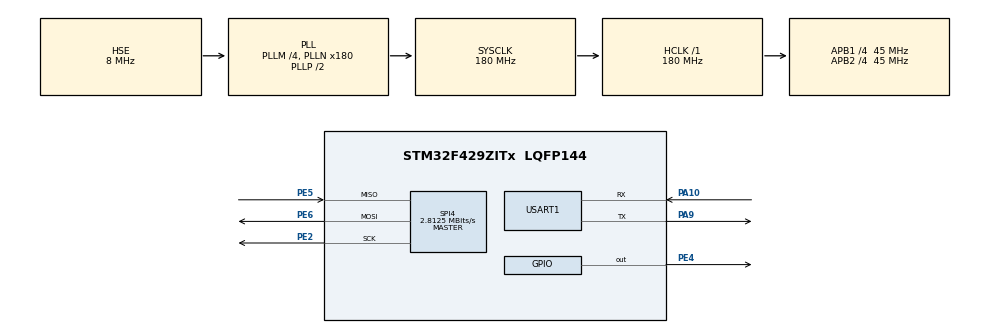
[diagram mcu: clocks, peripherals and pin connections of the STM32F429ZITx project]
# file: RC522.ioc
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Mcu.Family=STM32F4
Mcu.Name=STM32F429ZITx
Mcu.Package=LQFP144
NVIC.PriorityGroup=NVIC_PRIORITYGROUP_4
PA10.Mode=Asynchronous
PA10.Signal=USART1_RX
PA9.Mode=Asynchronous
PA9.Signal=USART1_TX
PE2.Mode=Full_Duplex_Master
PE2.Signal=SPI4_SCK
PE4.Signal=GPIO_Output
PE5.Mode=Full_Duplex_Master
PE5.Signal=SPI4_MISO
PE6.Mode=Full_Duplex_Master
PE6.Signal=SPI4_MOSI
PH0/OSC_IN.Mode=HSE-External-Oscillator
PH0/OSC_IN.Signal=RCC_OSC_IN
PH1/OSC_OUT.Mode=HSE-External-Oscillator
PH1/OSC_OUT.Signal=RCC_OSC_OUT
ProjectManager.HeapSize=0x200
ProjectManager.StackSize=0x400
ProjectManager.TargetToolchain=STM32CubeIDE
RCC.48MHZClocksFreq_Value=90000000
RCC.AHBFreq_Value=180000000
RCC.APB1CLKDivider=RCC_HCLK_DIV4
RCC.APB1Freq_Value=45000000
RCC.APB1TimFreq_Value=90000000
RCC.APB2CLKDivider=RCC_HCLK_DIV4
RCC.APB2Freq_Value=45000000
RCC.APB2TimFreq_Value=90000000
RCC.CortexFreq_Value=180000000
RCC.HCLKFreq_Value=180000000
RCC.HSE_VALUE=8000000
RCC.HSI_VALUE=16000000
RCC.LSE_VALUE=32768
RCC.PLLM=4
RCC.PLLN=180
RCC.PLLSourceVirtual=RCC_PLLSOURCE_HSE
RCC.SYSCLKFreq_VALUE=180000000
RCC.SYSCLKSource=RCC_SYSCLKSOURCE_PLLCLK
RCC.VCOOutputFreq_Value=360000000
SPI4.BaudRatePrescaler=SPI_BAUDRATEPRESCALER_16
SPI4.CalculateBaudRate=2.8125 MBits/s
SPI4.Direction=SPI_DIRECTION_2LINES
SPI4.Mode=SPI_MODE_MASTER
SPI4.VirtualType=VM_MASTER
USART1.VirtualMode=VM_ASYNC
board=custom

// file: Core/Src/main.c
/* USER CODE BEGIN Header */
/**
  ******************************************************************************
  * @file           : main.c
  * @brief          : Main program body
  ******************************************************************************
  * @attention
  *
  * Copyright (c) 2025 STMicroelectronics.
  * All rights reserved.
  *
  * This software is licensed under terms that can be found in the LICENSE file
  * in the root directory of this software component.
  * If no LICENSE file comes with this software, it is provided AS-IS.
  *
  ******************************************************************************
  */
/* USER CODE END Header */
#include "main.h"

/* USER CODE BEGIN Includes */
#include "tm_stm32f4_mfrc522.h"
/* USER CODE END Includes */

SPI_HandleTypeDef hspi4;

UART_HandleTypeDef huart1;

void SystemClock_Config(void);
static void MX_GPIO_Init(void);
static void MX_SPI4_Init(void);
static void MX_USART1_UART_Init(void);

int main(void)
{

  /* MCU Configuration--------------------------------------------------------*/

  /* Reset of all peripherals, Initializes the Flash interface and the Systick. */
  HAL_Init();

  /* Configure the system clock */
  SystemClock_Config();

  /* USER CODE BEGIN SysInit */
  TM_MFRC522_Init();
  /* USER CODE END SysInit */

  /* Initialize all configured peripherals */
  MX_GPIO_Init();
  MX_SPI4_Init();
  MX_USART1_UART_Init();
  /* USER CODE BEGIN 2 */
  char buf[100];

  /* USER CODE END 2 */

  /* Infinite loop */
  /* USER CODE BEGIN WHILE */
  while (1)
  {
	  uint8_t CardID[5];
	  HAL_Delay(100);
	  if (TM_MFRC522_Check(CardID) == MI_OK) {
		  sprintf (buf, "%s", "RFID Card Found!\r\n");
		  HAL_UART_Transmit(&huart1,(const uint8_t*) buf, strlen(buf), 2);
		  HAL_Delay(300);
	  }
	  else{
		  sprintf (buf, "%s", "RFID Card Not Found!\r\n");
		  HAL_UART_Transmit(&huart1,(const uint8_t*) buf, strlen(buf), 2);
		  HAL_Delay(300);

	  }
    /* USER CODE END WHILE */

  }
}

void SystemClock_Config(void)
{
  RCC_OscInitTypeDef RCC_OscInitStruct = {0};
  RCC_ClkInitTypeDef RCC_ClkInitStruct = {0};

  /** Configure the main internal regulator output voltage
  */
  __HAL_RCC_PWR_CLK_ENABLE();
  __HAL_PWR_VOLTAGESCALING_CONFIG(PWR_REGULATOR_VOLTAGE_SCALE1);

  /** Initializes the RCC Oscillators according to the specified parameters
  * in the RCC_OscInitTypeDef structure.
  */
  RCC_OscInitStruct.OscillatorType = RCC_OSCILLATORTYPE_HSE;
  RCC_OscInitStruct.HSEState = RCC_HSE_ON;
  RCC_OscInitStruct.PLL.PLLState = RCC_PLL_ON;
  RCC_OscInitStruct.PLL.PLLSource = RCC_PLLSOURCE_HSE;
  RCC_OscInitStruct.PLL.PLLM = 4;
  RCC_OscInitStruct.PLL.PLLN = 180;
  RCC_OscInitStruct.PLL.PLLP = RCC_PLLP_DIV2;
  RCC_OscInitStruct.PLL.PLLQ = 4;
  if (HAL_RCC_OscConfig(&RCC_OscInitStruct) != HAL_OK)
  {
    Error_Handler();
  }

  /** Activate the Over-Drive mode
  */
  if (HAL_PWREx_EnableOverDrive() != HAL_OK)
  {
    Error_Handler();
  }

  /** Initializes the CPU, AHB and APB buses clocks
  */
  RCC_ClkInitStruct.ClockType = RCC_CLOCKTYPE_HCLK|RCC_CLOCKTYPE_SYSCLK
                              |RCC_CLOCKTYPE_PCLK1|RCC_CLOCKTYPE_PCLK2;
  RCC_ClkInitStruct.SYSCLKSource = RCC_SYSCLKSOURCE_PLLCLK;
  RCC_ClkInitStruct.AHBCLKDivider = RCC_SYSCLK_DIV1;
  RCC_ClkInitStruct.APB1CLKDivider = RCC_HCLK_DIV4;
  RCC_ClkInitStruct.APB2CLKDivider = RCC_HCLK_DIV4;

  if (HAL_RCC_ClockConfig(&RCC_ClkInitStruct, FLASH_LATENCY_5) != HAL_OK)
  {
    Error_Handler();
  }
}

static void MX_SPI4_Init(void)
{

  /* SPI4 parameter configuration*/
  hspi4.Instance = SPI4;
  hspi4.Init.Mode = SPI_MODE_MASTER;
  hspi4.Init.Direction = SPI_DIRECTION_2LINES;
  hspi4.Init.DataSize = SPI_DATASIZE_8BIT;
  hspi4.Init.CLKPolarity = SPI_POLARITY_LOW;
  hspi4.Init.CLKPhase = SPI_PHASE_1EDGE;
  hspi4.Init.NSS = SPI_NSS_SOFT;
  hspi4.Init.BaudRatePrescaler = SPI_BAUDRATEPRESCALER_16;
  hspi4.Init.FirstBit = SPI_FIRSTBIT_MSB;
  hspi4.Init.TIMode = SPI_TIMODE_DISABLE;
  hspi4.Init.CRCCalculation = SPI_CRCCALCULATION_DISABLE;
  hspi4.Init.CRCPolynomial = 10;
  if (HAL_SPI_Init(&hspi4) != HAL_OK)
  {
    Error_Handler();
  }

}

static void MX_USART1_UART_Init(void)
{

  huart1.Instance = USART1;
  huart1.Init.BaudRate = 115200;
  huart1.Init.WordLength = UART_WORDLENGTH_8B;
  huart1.Init.StopBits = UART_STOPBITS_1;
  huart1.Init.Parity = UART_PARITY_NONE;
  huart1.Init.Mode = UART_MODE_TX_RX;
  huart1.Init.HwFlowCtl = UART_HWCONTROL_NONE;
  huart1.Init.OverSampling = UART_OVERSAMPLING_16;
  if (HAL_UART_Init(&huart1) != HAL_OK)
  {
    Error_Handler();
  }

}

static void MX_GPIO_Init(void)
{
  GPIO_InitTypeDef GPIO_InitStruct = {0};

  /* GPIO Ports Clock Enable */
  __HAL_RCC_GPIOE_CLK_ENABLE();
  __HAL_RCC_GPIOH_CLK_ENABLE();
  __HAL_RCC_GPIOA_CLK_ENABLE();

  /*Configure GPIO pin Output Level */
  HAL_GPIO_WritePin(GPIOE, GPIO_PIN_4, GPIO_PIN_RESET);

  /*Configure GPIO pin : PE4 */
  GPIO_InitStruct.Pin = GPIO_PIN_4;
  GPIO_InitStruct.Mode = GPIO_MODE_OUTPUT_PP;
  GPIO_InitStruct.Pull = GPIO_NOPULL;
  GPIO_InitStruct.Speed = GPIO_SPEED_FREQ_LOW;
  HAL_GPIO_Init(GPIOE, &GPIO_InitStruct);

}

void Error_Handler(void)
{
  __disable_irq();
  while (1)
  {
  }
}
